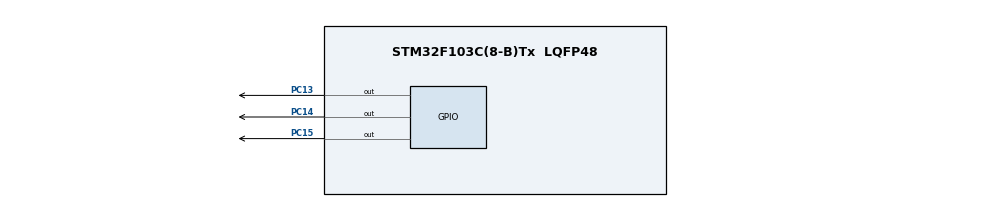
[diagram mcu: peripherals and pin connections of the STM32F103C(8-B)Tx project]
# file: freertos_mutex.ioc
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FREERTOS.Mutexes01=myMutex01,Dynamic,NULL,Available
FREERTOS.Tasks01=Task01,24,128,StartDefaultTask,Default,NULL,Dynamic,NULL,NULL;myTask02,8,128,StartTask02,Default,NULL,Dynamic,NULL,NULL;myTask03,8,128,StartTask03,Default,NULL,Dynamic,NULL,NULL
Mcu.Family=STM32F1
Mcu.Name=STM32F103C(8-B)Tx
Mcu.Package=LQFP48
NVIC.PriorityGroup=NVIC_PRIORITYGROUP_4
NVIC.TIM4_IRQn=true\:15\:0\:false\:false\:true\:false\:false\:true\:true
NVIC.TimeBase=TIM4_IRQn
NVIC.TimeBaseIP=TIM4
PA13.Mode=Trace_Asynchronous_SW
PA13.Signal=SYS_JTMS-SWDIO
PA14.Mode=Trace_Asynchronous_SW
PA14.Signal=SYS_JTCK-SWCLK
PB3.Mode=Trace_Asynchronous_SW
PB3.Signal=SYS_JTDO-TRACESWO
PC13-TAMPER-RTC.Signal=GPIO_Output
PC14-OSC32_IN.Signal=GPIO_Output
PC15-OSC32_OUT.Signal=GPIO_Output
ProjectManager.HeapSize=0x200
ProjectManager.StackSize=0x400
ProjectManager.TargetToolchain=STM32CubeIDE
RCC.APB1Freq_Value=8000000
RCC.APB2Freq_Value=8000000
VP_FREERTOS_VS_CMSIS_V2.Mode=CMSIS_V2
VP_SYS_VS_tim4.Mode=TIM4
board=custom

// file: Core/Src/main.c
/* USER CODE BEGIN Header */
/**
  ******************************************************************************
  * @file           : main.c
  * @brief          : Main program body
  ******************************************************************************
  * @attention
  *
  * Copyright (c) 2026 STMicroelectronics.
  * All rights reserved.
  *
  * This software is licensed under terms that can be found in the LICENSE file
  * in the root directory of this software component.
  * If no LICENSE file comes with this software, it is provided AS-IS.
  *
  ******************************************************************************
  */
/* USER CODE END Header */
#include "main.h"
#include "cmsis_os.h"

/* Definitions for Task01 */
osThreadId_t Task01Handle;
const osThreadAttr_t Task01_attributes = {
  .name = "Task01",
  .stack_size = 128 * 4,
  .priority = (osPriority_t) osPriorityNormal,
};
/* Definitions for myTask02 */
osThreadId_t myTask02Handle;
const osThreadAttr_t myTask02_attributes = {
  .name = "myTask02",
  .stack_size = 128 * 4,
  .priority = (osPriority_t) osPriorityLow,
};
/* Definitions for myTask03 */
osThreadId_t myTask03Handle;
const osThreadAttr_t myTask03_attributes = {
  .name = "myTask03",
  .stack_size = 128 * 4,
  .priority = (osPriority_t) osPriorityLow,
};
/* Definitions for myMutex01 */
osMutexId_t myMutex01Handle;
const osMutexAttr_t myMutex01_attributes = {
  .name = "myMutex01"
};

void SystemClock_Config(void);
static void MX_GPIO_Init(void);
void StartDefaultTask(void *argument);
void StartTask02(void *argument);
void StartTask03(void *argument);

int main(void)
{

  /* MCU Configuration--------------------------------------------------------*/

  /* Reset of all peripherals, Initializes the Flash interface and the Systick. */
  HAL_Init();

  /* Configure the system clock */
  SystemClock_Config();

  /* Initialize all configured peripherals */
  MX_GPIO_Init();

  /* Init scheduler */
  osKernelInitialize();
  /* Create the mutex(es) */
  /* creation of myMutex01 */
  myMutex01Handle = osMutexNew(&myMutex01_attributes);

  /* Create the thread(s) */
  /* creation of Task01 */
  Task01Handle = osThreadNew(StartDefaultTask, NULL, &Task01_attributes);

  /* creation of myTask02 */
  myTask02Handle = osThreadNew(StartTask02, NULL, &myTask02_attributes);

  /* creation of myTask03 */
  myTask03Handle = osThreadNew(StartTask03, NULL, &myTask03_attributes);

  /* Start scheduler */
  osKernelStart();

  /* We should never get here as control is now taken by the scheduler */

  /* Infinite loop */
  while (1)
  {

  }
}

void SystemClock_Config(void)
{
  RCC_OscInitTypeDef RCC_OscInitStruct = {0};
  RCC_ClkInitTypeDef RCC_ClkInitStruct = {0};

  /** Initializes the RCC Oscillators according to the specified parameters
  * in the RCC_OscInitTypeDef structure.
  */
  RCC_OscInitStruct.OscillatorType = RCC_OSCILLATORTYPE_HSI;
  RCC_OscInitStruct.HSIState = RCC_HSI_ON;
  RCC_OscInitStruct.HSICalibrationValue = RCC_HSICALIBRATION_DEFAULT;
  RCC_OscInitStruct.PLL.PLLState = RCC_PLL_NONE;
  if (HAL_RCC_OscConfig(&RCC_OscInitStruct) != HAL_OK)
  {
    Error_Handler();
  }

  /** Initializes the CPU, AHB and APB buses clocks
  */
  RCC_ClkInitStruct.ClockType = RCC_CLOCKTYPE_HCLK|RCC_CLOCKTYPE_SYSCLK
                              |RCC_CLOCKTYPE_PCLK1|RCC_CLOCKTYPE_PCLK2;
  RCC_ClkInitStruct.SYSCLKSource = RCC_SYSCLKSOURCE_HSI;
  RCC_ClkInitStruct.AHBCLKDivider = RCC_SYSCLK_DIV1;
  RCC_ClkInitStruct.APB1CLKDivider = RCC_HCLK_DIV1;
  RCC_ClkInitStruct.APB2CLKDivider = RCC_HCLK_DIV1;

  if (HAL_RCC_ClockConfig(&RCC_ClkInitStruct, FLASH_LATENCY_0) != HAL_OK)
  {
    Error_Handler();
  }
}

static void MX_GPIO_Init(void)
{
  GPIO_InitTypeDef GPIO_InitStruct = {0};

  /* GPIO Ports Clock Enable */
  __HAL_RCC_GPIOC_CLK_ENABLE();
  __HAL_RCC_GPIOA_CLK_ENABLE();
  __HAL_RCC_GPIOB_CLK_ENABLE();

  /*Configure GPIO pin Output Level */
  HAL_GPIO_WritePin(GPIOC, GPIO_PIN_13|GPIO_PIN_14|GPIO_PIN_15, GPIO_PIN_RESET);

  /*Configure GPIO pins : PC13 PC14 PC15 */
  GPIO_InitStruct.Pin = GPIO_PIN_13|GPIO_PIN_14|GPIO_PIN_15;
  GPIO_InitStruct.Mode = GPIO_MODE_OUTPUT_PP;
  GPIO_InitStruct.Pull = GPIO_NOPULL;
  GPIO_InitStruct.Speed = GPIO_SPEED_FREQ_LOW;
  HAL_GPIO_Init(GPIOC, &GPIO_InitStruct);

}

void StartDefaultTask(void *argument)
{
  /* USER CODE BEGIN 5 */
  /* Infinite loop */
  for(;;)
  {
    osMutexAcquire(myMutex01Handle, osWaitForever);
    HAL_GPIO_TogglePin(GPIOC, GPIO_PIN_13);
    osDelay(400);
    HAL_GPIO_TogglePin(GPIOC, GPIO_PIN_13);
    osDelay(100);
    osMutexRelease(myMutex01Handle);
  }
  /* USER CODE END 5 */
}

void StartTask02(void *argument)
{
  /* USER CODE BEGIN StartTask02 */
  /* Infinite loop */
  for(;;)
  {
	    osMutexAcquire(myMutex01Handle, osWaitForever);
	    HAL_GPIO_TogglePin(GPIOC, GPIO_PIN_14);
	    osDelay(400);
	    HAL_GPIO_TogglePin(GPIOC, GPIO_PIN_14);
	    osDelay(100);
	    osMutexRelease(myMutex01Handle);
  }
  /* USER CODE END StartTask02 */
}

void StartTask03(void *argument)
{
  /* USER CODE BEGIN StartTask03 */
  /* Infinite loop */
  for(;;)
  {
	    osMutexAcquire(myMutex01Handle, osWaitForever);
	    HAL_GPIO_TogglePin(GPIOC, GPIO_PIN_15);
	    osDelay(400);
	    HAL_GPIO_TogglePin(GPIOC, GPIO_PIN_15);
	    osDelay(100);
	    osMutexRelease(myMutex01Handle);
  }
  /* USER CODE END StartTask03 */
}

void HAL_TIM_PeriodElapsedCallback(TIM_HandleTypeDef *htim)
{
  if (htim->Instance == TIM4)
  {
    HAL_IncTick();
  }
}

void Error_Handler(void)
{
  __disable_irq();
  while (1)
  {
  }
}
